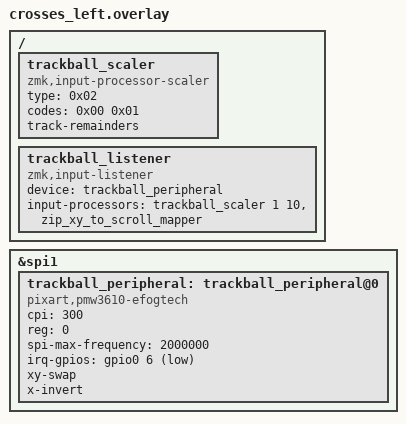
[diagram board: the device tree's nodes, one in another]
/* config/crosses_left.overlay */

&spi1 {
    trackball_peripheral: trackball_peripheral@0 {
        cpi = <300>;
        status = "okay";
        compatible = "pixart,pmw3610-efogtech";
        reg = <0>;
        spi-max-frequency = <2000000>;
        irq-gpios = <&gpio0 6 (GPIO_ACTIVE_LOW | GPIO_PULL_UP)>;
        xy-swap;
        x-invert;
    };
};

/ {
    trackball_scaler: trackball_scaler {
        compatible = "zmk,input-processor-scaler";
        #input-processor-cells = <2>;
        type = <0x02>;
        codes = <0x00 0x01>;
        track-remainders;
    };

    trackball_listener {
        compatible = "zmk,input-listener";
        device = <&trackball_peripheral>;
        input-processors = <&trackball_scaler 1 10>, <&zip_xy_to_scroll_mapper>;
    };
};
